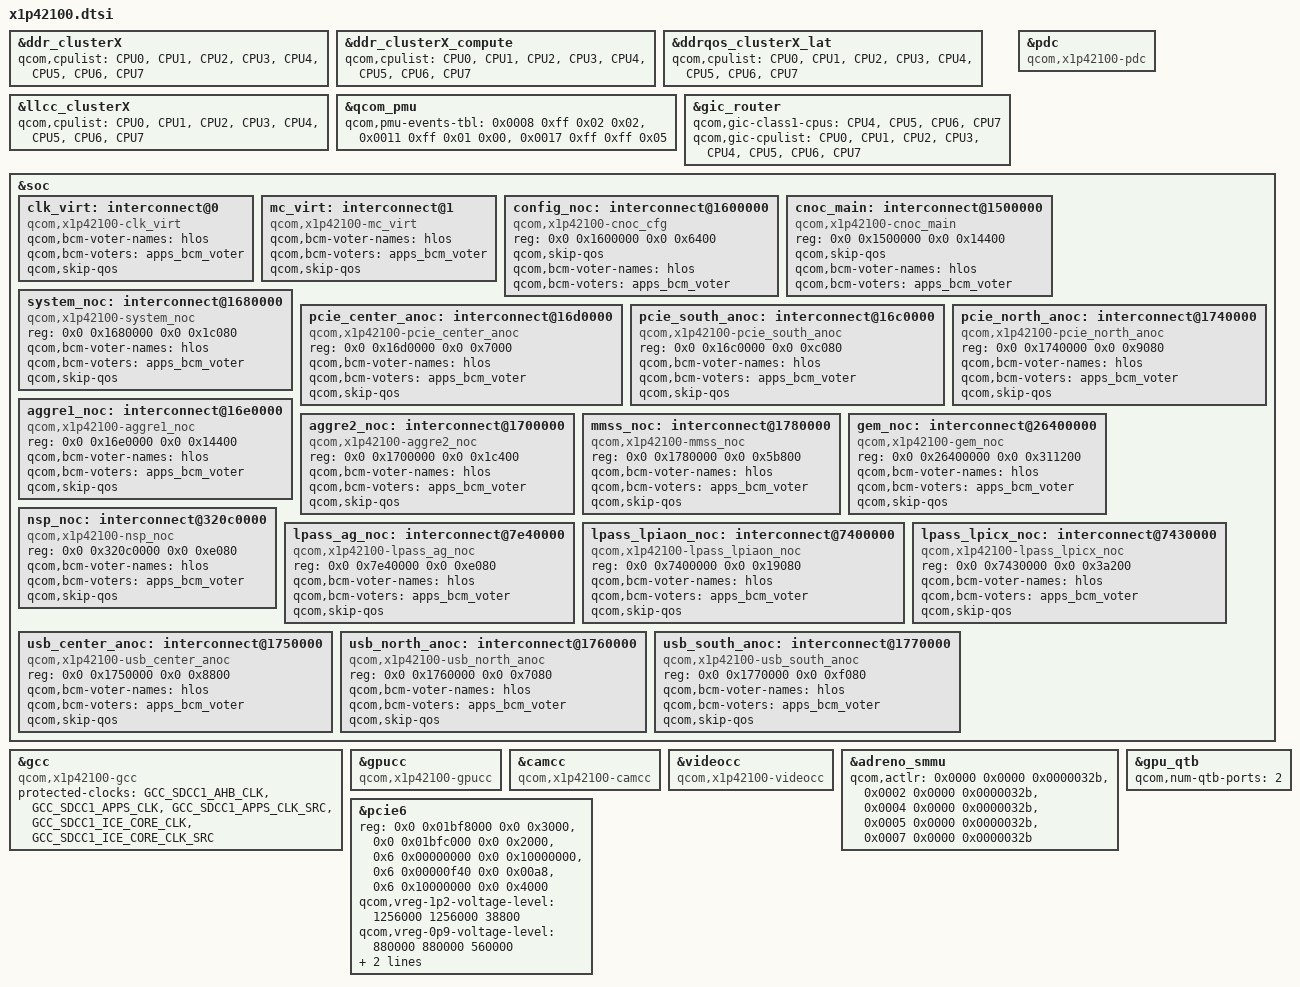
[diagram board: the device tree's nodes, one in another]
// SPDX-License-Identifier: BSD-3-Clause
/*
 * Copyright (c) Qualcomm Technologies, Inc. and/or its subsidiaries.
 */

/* X1P42100 is heavily based on X1E80100, with some meaningful differences */
#include "x1e80100.dtsi"
#include "x1p42100-coresight.dtsi"
#include "x1p42100-regulators.dtsi"
#include "x1e80100-pmic-overlay.dtsi"
#include "x1p42100-thermal-overlay.dtsi"
#include "x1p42100-debug.dtsi"
#include <dt-bindings/interconnect/qcom,icc.h>
#include <dt-bindings/interconnect/qcom,x1p42100.h>
#include <dt-bindings/clock/qcom,x1p42100-gcc.h>
#include <dt-bindings/clock/qcom,x1p42100-videocc.h>

/delete-node/ &CPU8;
/delete-node/ &CPU9;
/delete-node/ &CPU10;
/delete-node/ &CPU11;
/delete-node/ &cpu_map_cluster2;
/delete-node/ &cluster_device2;

&ddr_clusterX {
	qcom,cpulist = <&CPU0 &CPU1 &CPU2 &CPU3 &CPU4 &CPU5 &CPU6 &CPU7>;
};

&ddr_clusterX_compute {
	qcom,cpulist = <&CPU0 &CPU1 &CPU2 &CPU3 &CPU4 &CPU5 &CPU6 &CPU7>;
};

&ddrqos_clusterX_lat {
	qcom,cpulist = <&CPU0 &CPU1 &CPU2 &CPU3 &CPU4 &CPU5 &CPU6 &CPU7>;
};

&llcc_clusterX {
	qcom,cpulist = <&CPU0 &CPU1 &CPU2 &CPU3 &CPU4 &CPU5 &CPU6 &CPU7>;
};

&qcom_pmu {
	qcom,pmu-events-tbl =
		< 0x0008 0xff 0x02 0x02 >,
		< 0x0011 0xff 0x01 0x00 >,
		< 0x0017 0xff 0xff 0x05 >;
};

&gic_router {
	qcom,gic-class1-cpus = <&CPU4 &CPU5 &CPU6 &CPU7>;
	qcom,gic-cpulist = <&CPU0 &CPU1 &CPU2 &CPU3 &CPU4 &CPU5 &CPU6 &CPU7>;
};

&pdc {
	compatible = "qcom,x1p42100-pdc", "qcom,pdc";
};

&soc {
	clk_virt: interconnect@0 {
		compatible = "qcom,x1p42100-clk_virt";
		#interconnect-cells = <1>;
		qcom,bcm-voter-names = "hlos";
		qcom,bcm-voters = <&apps_bcm_voter>;
		qcom,skip-qos;
	};

	mc_virt: interconnect@1 {
		compatible = "qcom,x1p42100-mc_virt";
		#interconnect-cells = <1>;
		qcom,bcm-voter-names = "hlos";
		qcom,bcm-voters = <&apps_bcm_voter>;
		qcom,skip-qos;
	};

	config_noc: interconnect@1600000 {
		compatible = "qcom,x1p42100-cnoc_cfg";
		reg = <0x0 0x1600000 0x0 0x6400>;
		#interconnect-cells = <1>;
		qcom,skip-qos;
		qcom,bcm-voter-names = "hlos";
		qcom,bcm-voters = <&apps_bcm_voter>;
	};

	cnoc_main: interconnect@1500000 {
		compatible = "qcom,x1p42100-cnoc_main";
		reg = <0x0 0x1500000 0x0 0x14400>;
		#interconnect-cells = <1>;
		qcom,skip-qos;
		qcom,bcm-voter-names = "hlos";
		qcom,bcm-voters = <&apps_bcm_voter>;
	};

	system_noc: interconnect@1680000 {
		compatible = "qcom,x1p42100-system_noc";
		reg = <0x0 0x1680000 0x0 0x1c080>;
		#interconnect-cells = <1>;
		qcom,bcm-voter-names = "hlos";
		qcom,bcm-voters = <&apps_bcm_voter>;
		qcom,skip-qos;
	};

	pcie_center_anoc: interconnect@16d0000 {
		compatible = "qcom,x1p42100-pcie_center_anoc";
		reg = <0x0 0x16d0000 0x0 0x7000>;
		#interconnect-cells = <1>;
		qcom,bcm-voter-names = "hlos";
		qcom,bcm-voters = <&apps_bcm_voter>;
		qcom,skip-qos;
	};

	pcie_south_anoc: interconnect@16c0000 {
		compatible = "qcom,x1p42100-pcie_south_anoc";
		reg = <0x0 0x16c0000 0x0 0xc080>;
		#interconnect-cells = <1>;
		qcom,bcm-voter-names = "hlos";
		qcom,bcm-voters = <&apps_bcm_voter>;
		qcom,skip-qos;
	};

	pcie_north_anoc: interconnect@1740000 {
		compatible = "qcom,x1p42100-pcie_north_anoc";
		reg = <0x0 0x1740000 0x0 0x9080>;
		#interconnect-cells = <1>;
		qcom,bcm-voter-names = "hlos";
		qcom,bcm-voters = <&apps_bcm_voter>;
		qcom,skip-qos;
	};

	aggre1_noc: interconnect@16e0000 {
		compatible = "qcom,x1p42100-aggre1_noc";
		reg = <0x0 0x16e0000 0x0 0x14400>;
		#interconnect-cells = <1>;
		qcom,bcm-voter-names = "hlos";
		qcom,bcm-voters = <&apps_bcm_voter>;
		qcom,skip-qos;
	};

	aggre2_noc: interconnect@1700000 {
		compatible = "qcom,x1p42100-aggre2_noc";
		reg = <0x0 0x1700000 0x0 0x1c400>;
		#interconnect-cells = <1>;
		qcom,bcm-voter-names = "hlos";
		qcom,bcm-voters = <&apps_bcm_voter>;
		qcom,skip-qos;
	};

	mmss_noc: interconnect@1780000 {
		compatible = "qcom,x1p42100-mmss_noc";
		reg = <0x0 0x1780000 0x0 0x5b800>;
		#interconnect-cells = <1>;
		qcom,bcm-voter-names = "hlos";
		qcom,bcm-voters = <&apps_bcm_voter>;
		qcom,skip-qos;
	};

	gem_noc: interconnect@26400000 {
		compatible = "qcom,x1p42100-gem_noc";
		reg = <0x0 0x26400000 0x0 0x311200>;
		#interconnect-cells = <1>;
		qcom,bcm-voter-names = "hlos";
		qcom,bcm-voters = <&apps_bcm_voter>;
		qcom,skip-qos;
	};

	nsp_noc: interconnect@320c0000 {
		compatible = "qcom,x1p42100-nsp_noc";
		reg = <0x0 0x320c0000 0x0 0xe080>;
		#interconnect-cells = <1>;
		qcom,bcm-voter-names = "hlos";
		qcom,bcm-voters = <&apps_bcm_voter>;
		qcom,skip-qos;
	};

	lpass_ag_noc: interconnect@7e40000 {
		compatible = "qcom,x1p42100-lpass_ag_noc";
		reg = <0x0 0x7e40000 0x0 0xe080>;
		#interconnect-cells = <1>;
		qcom,bcm-voter-names = "hlos";
		qcom,bcm-voters = <&apps_bcm_voter>;
		qcom,skip-qos;
	};

	lpass_lpiaon_noc: interconnect@7400000 {
		compatible = "qcom,x1p42100-lpass_lpiaon_noc";
		reg = <0x0 0x7400000 0x0 0x19080>;
		#interconnect-cells = <1>;
		qcom,bcm-voter-names = "hlos";
		qcom,bcm-voters = <&apps_bcm_voter>;
		qcom,skip-qos;
	};

	lpass_lpicx_noc: interconnect@7430000 {
		compatible = "qcom,x1p42100-lpass_lpicx_noc";
		reg = <0x0 0x7430000 0x0 0x3a200>;
		#interconnect-cells = <1>;
		qcom,bcm-voter-names = "hlos";
		qcom,bcm-voters = <&apps_bcm_voter>;
		qcom,skip-qos;
	};

	usb_center_anoc: interconnect@1750000 {
		compatible = "qcom,x1p42100-usb_center_anoc";
		reg = <0x0 0x1750000 0x0 0x8800>;
		#interconnect-cells = <1>;
		qcom,bcm-voter-names = "hlos";
		qcom,bcm-voters = <&apps_bcm_voter>;
		qcom,skip-qos;
	};

	usb_north_anoc: interconnect@1760000 {
		compatible = "qcom,x1p42100-usb_north_anoc";
		reg = <0x0 0x1760000 0x0 0x7080>;
		#interconnect-cells = <1>;
		qcom,bcm-voter-names = "hlos";
		qcom,bcm-voters = <&apps_bcm_voter>;
		qcom,skip-qos;
	};

	usb_south_anoc: interconnect@1770000 {
		compatible = "qcom,x1p42100-usb_south_anoc";
		reg = <0x0 0x1770000 0x0 0xf080>;
		#interconnect-cells = <1>;
		qcom,bcm-voter-names = "hlos";
		qcom,bcm-voters = <&apps_bcm_voter>;
		qcom,skip-qos;
	};

};

&gcc {
	compatible = "qcom,x1p42100-gcc", "syscon";
	protected-clocks = <GCC_SDCC1_AHB_CLK>, <GCC_SDCC1_APPS_CLK>,
			<GCC_SDCC1_APPS_CLK_SRC>, <GCC_SDCC1_ICE_CORE_CLK>,
			<GCC_SDCC1_ICE_CORE_CLK_SRC>;
};

&gpucc {
	compatible = "qcom,x1p42100-gpucc", "syscon";
};

&camcc {
	compatible = "qcom,x1p42100-camcc", "syscon";
};

&videocc {
	compatible = "qcom,x1p42100-videocc", "syscon";
};

&adreno_smmu {
	qcom,actlr =
		<0x0000 0x0000 0x0000032b>,
		<0x0002 0x0000 0x0000032b>,
		<0x0004 0x0000 0x0000032b>,
		<0x0005 0x0000 0x0000032b>,
		<0x0007 0x0000 0x0000032b>;
};

&gpu_qtb {
	qcom,num-qtb-ports = <2>;
};

&pcie6 {
	reg = <0x0 0x01bf8000 0x0 0x3000>,
		<0x0 0x01bfc000 0x0 0x2000>,
		<0x6 0x00000000 0x0 0x10000000>,
		<0x6 0x00000f40 0x0 0x00a8>,
		<0x6 0x10000000 0x0 0x4000>;
	reg-names = "parf", "phy", "dm_core", "elbi", "iatu";

	/* <max min opt> */
	qcom,vreg-1p2-voltage-level = <1256000 1256000 38800>;
	qcom,vreg-0p9-voltage-level = <880000 880000 560000>;

	/delete-property/ qcom,bifurcation-capable;
	/delete-property/ qcom,tcsr-pcie-link-config-offset;
	/delete-property/ qcom,tcsr-pcie-link-config-value;
	/delete-property/ qcom,tcsr-pcie-link-config-mask;
	/delete-property/ qcom,phy-sw-reset-offset;
	/delete-property/ qcom,phy-start-cntrl-offset;

	qcom,phy-sequence = <0x1240 0x03 0x0
		0x0030 0x1d 0x0
		0x0034 0x03 0x0
		0x0078 0x01 0x0
		0x007c 0x10 0x0
		0x0080 0x90 0x0
		0x00ac 0x34 0x0
		0x0208 0x0c 0x0
		0x0218 0x04 0x0
		0x020c 0x0a 0x0
		0x021c 0x05 0x0
		0x0220 0x16 0x0
		0x0234 0x00 0x0
		0x029c 0x82 0x0
		0x02a0 0x00 0x0
		0x042c 0x12 0x0
		0x02ac 0x01 0x0
		0x02b0 0x01 0x0
		0x02b4 0x45 0x0
		0x02e8 0x0a 0x0
		0x02e0 0x00 0x0
		0x030c 0x0d 0x0
		0x0320 0x0b 0x0
		0x0348 0x1c 0x0
		0x0388 0x20 0x0
		0x0394 0x38 0x0
		0x03dc 0x01 0x0
		0x03f4 0x14 0x0
		0x03f8 0xb3 0x0
		0x03fc 0x58 0x0
		0x0400 0x9a 0x0
		0x0404 0x28 0x0
		0x0408 0xb6 0x0
		0x040c 0xee 0x0
		0x0410 0xe4 0x0
		0x0414 0xa4 0x0
		0x0418 0x60 0x0
		0x041c 0xdf 0x0
		0x0420 0x4b 0x0
		0x0424 0x76 0x0
		0x0428 0xff 0x0
		0x02d4 0x10 0x0
		0x0830 0x1d 0x0
		0x0834 0x03 0x0
		0x0878 0x01 0x0
		0x087c 0x10 0x0
		0x0880 0x90 0x0
		0x08ac 0x34 0x0
		0x0a08 0x0c 0x0
		0x0a18 0x04 0x0
		0x0a0c 0x0a 0x0
		0x0a1c 0x05 0x0
		0x0a20 0x16 0x0
		0x0a34 0x00 0x0
		0x0a9c 0x82 0x0
		0x0aa0 0x00 0x0
		0x0c2c 0x12 0x0
		0x0aac 0x01 0x0
		0x0ab0 0x01 0x0
		0x0ab4 0x45 0x0
		0x0ae8 0x0b 0x0
		0x0ae0 0x00 0x0
		0x0b0c 0x0d 0x0
		0x0b20 0x0b 0x0
		0x0b48 0x1c 0x0
		0x0b88 0x20 0x0
		0x0b94 0x38 0x0
		0x0bdc 0x01 0x0
		0x0bf4 0x14 0x0
		0x0bf8 0xb3 0x0
		0x0bfc 0x58 0x0
		0x0c00 0x9a 0x0
		0x0c04 0x28 0x0
		0x0c08 0xb6 0x0
		0x0c0c 0xee 0x0
		0x0c10 0xe4 0x0
		0x0c14 0xa4 0x0
		0x0c18 0x60 0x0
		0x0c1c 0xdf 0x0
		0x0c20 0x4b 0x0
		0x0c24 0x76 0x0
		0x0c28 0xff 0x0
		0x0ad4 0x10 0x0
		0x0ea0 0x01 0x0
		0x0eb4 0x88 0x0
		0x0ec4 0x02 0x0
		0x0ec8 0x0d 0x0
		0x0ed4 0xd4 0x0
		0x0ed8 0x12 0x0
		0x0edc 0xdb 0x0
		0x0ee0 0x9a 0x0
		0x0ee4 0x32 0x0
		0x0ee8 0xb6 0x0
		0x0eec 0x64 0x0
		0x0ef0 0x1f 0x0
		0x0ef4 0x1f 0x0
		0x0ef8 0x1f 0x0
		0x0efc 0x1f 0x0
		0x0f00 0x1f 0x0
		0x0f04 0x1f 0x0
		0x0f0c 0x1f 0x0
		0x0f14 0x1f 0x0
		0x0f1c 0x1f 0x0
		0x0f28 0x5b 0x0
		0x1000 0x26 0x0
		0x1004 0x03 0x0
		0x1010 0x06 0x0
		0x1014 0x16 0x0
		0x1018 0x36 0x0
		0x101c 0x04 0x0
		0x1020 0x0a 0x0
		0x1024 0x1a 0x0
		0x1028 0x68 0x0
		0x1030 0xab 0x0
		0x1034 0xaa 0x0
		0x1038 0x02 0x0
		0x103c 0x12 0x0
		0x1060 0xf8 0x0
		0x1064 0x01 0x0
		0x1070 0x06 0x0
		0x1074 0x16 0x0
		0x1078 0x36 0x0
		0x107c 0x0a 0x0
		0x1080 0x04 0x0
		0x1084 0x0d 0x0
		0x1088 0x41 0x0
		0x1090 0xab 0x0
		0x1094 0xaa 0x0
		0x1098 0x01 0x0
		0x109c 0x00 0x0
		0x10bc 0x0a 0x0
		0x10c0 0x01 0x0
		0x10cc 0x62 0x0
		0x10d0 0x02 0x0
		0x10d8 0x40 0x0
		0x10dc 0x1c 0x0
		0x10e0 0x90 0x0
		0x10e4 0x82 0x0
		0x10f4 0x0f 0x0
		0x1110 0x08 0x0
		0x1120 0x46 0x0
		0x1124 0x04 0x0
		0x1140 0x14 0x0
		0x1164 0x34 0x0
		0x1170 0xa0 0x0
		0x1174 0x06 0x0
		0x1184 0x88 0x0
		0x1188 0x14 0x0
		0x1198 0x0f 0x0
		0x1378 0x2e 0x0
		0x1390 0xaa 0x0
		0x13f8 0x00 0x0
		0x13fc 0x22 0x0
		0x141c 0xc1 0x0
		0x1490 0x00 0x0
		0x14a0 0x16 0x0
		0x1508 0x02 0x0
		0x155c 0x2e 0x0
		0x157c 0x03 0x0
		0x1584 0x28 0x0
		0x158c 0x18 0x0
		0x15ac 0x7a 0x0
		0x15c0 0x8a 0x0
		0x14f0 0x27 0x0
		0x14f4 0x27 0x0
		0x13dc 0x04 0x0
		0x13e0 0x02 0x0
		0x1418 0xc0 0x0
		0x140c 0x1d 0x0
		0x1a38 0x00 0x0
		0x1e38 0x00 0x0
		0x1e24 0x00 0x0
		0x1e28 0x00 0x0
		0x1200 0x00 0x0
		0x1244 0x03 0x0>;

	status = "okay";
};
